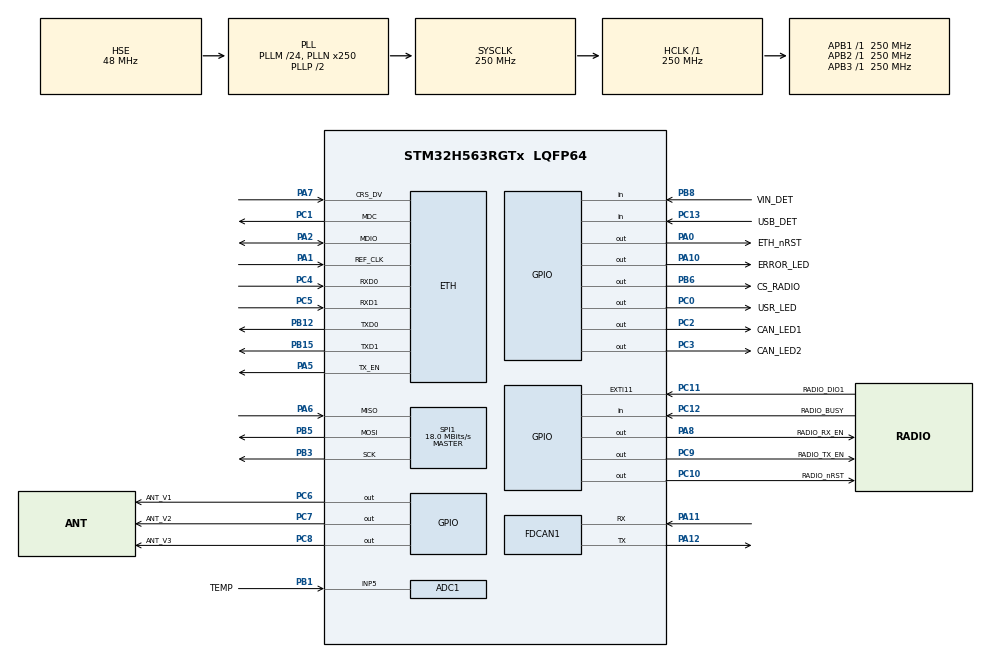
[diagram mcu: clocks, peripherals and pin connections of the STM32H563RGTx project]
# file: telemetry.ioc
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ADC1.Channel-1\#ChannelRegularConversion=ADC_CHANNEL_5
ADC1.MonitoredBy-1\#ChannelRegularConversion=__NULL
ADC1.NbrOfConversionFlag=1
ADC1.OffsetNumber-1\#ChannelRegularConversion=ADC_OFFSET_NONE
ADC1.Rank-1\#ChannelRegularConversion=1
ADC1.SamplingTime-1\#ChannelRegularConversion=ADC_SAMPLETIME_247CYCLES_5
ADC1.master=1
BOOTPATH.BootPathName=LEGACY
BOOTPATH.UserSelectedBootPath=LEGACY
CORTEX_M33_NS.AccessPermission-Cortex_Memory_Protection_Unit_Region1_Settings=MPU_REGION_ALL_RW
CORTEX_M33_NS.Attributes1=__NULL
CORTEX_M33_NS.BaseAddress-Cortex_Memory_Protection_Unit_Region1_Settings=0x20000000
CORTEX_M33_NS.DisableExec-Cortex_Memory_Protection_Unit_Region1_Settings=MPU_INSTRUCTION_ACCESS_DISABLE
CORTEX_M33_NS.Enable-Cortex_Memory_Protection_Unit_Region1_Settings=MPU_REGION_ENABLE
CORTEX_M33_NS.LimitAddress-Cortex_Memory_Protection_Unit_Region1_Settings=0x20050000
CORTEX_M33_NS.Number-Cortex_Memory_Protection_Unit_Region0_OTP_RO_AREAS_Settings=MPU_REGION_NUMBER0
CORTEX_M33_NS.default_mode_Activation=1
CORTEX_M33_NS.userName=CORTEX_M33
ETH.MediaInterface=HAL_ETH_RMII_MODE
FDCAN1.CalculateBaudRateNominal=833333
FDCAN1.CalculateTimeBitNominal=1200
FDCAN1.CalculateTimeQuantumNominal=400.0
Mcu.Family=STM32H5
Mcu.Name=STM32H563RGTx
Mcu.Package=LQFP64
NETXDUO.ETH_ON=1
NETXDUO.Initialize_ICMP_protocol=true
NETXDUO.Initialize_TCP_protocol=false
NETXDUO.LAN_8742=1
NETXDUO.NX_APP_IP_INSTANCE_THREAD_SIZE=2048
NETXDUO.NX_APP_MEM_POOL_SIZE=40*1024
NETXDUO.NX_APP_PACKET_POOL_SIZE=20
NETXDUO.NX_ENABLE_INTERFACE_CAPABILITY=false
NETXDUO.NetXDuo_Generate_Init_Code=true
NETXDUO.NetXDuo_Static_IP_address=192.168.1.50
NVIC.ETH_IRQn=true\:0\:0\:false\:false\:true\:false\:true\:true\:true
NVIC.EXTI11_IRQn=true\:0\:0\:false\:false\:true\:false\:true\:true\:true
NVIC.PriorityGroup=NVIC_PRIORITYGROUP_4
NVIC.TIM1_UP_IRQn=true\:15\:0\:false\:false\:true\:false\:false\:true\:true
NVIC.TIM2_IRQn=true\:0\:0\:false\:false\:false\:false\:true\:true\:true
NVIC.TimeBase=TIM1_UP_IRQn
NVIC.TimeBaseIP=TIM1
NetXDuo.BSP.number=1
NetXDuo0.BSP.STBoard=false
NetXDuo0.BSP.api=BSP_COMPONENT_DRIVER
NetXDuo0.BSP.component=lan8742
NetXDuo0.BSP.instance=lan8742
NetXDuo0.BSP.name=LAN_Component
NetXDuo0.BSP.semaphore=SEMA_lan8742
NetXDuo0.BSP.solution=lan8742
PA0.GPIO_Label=ETH_nRST
PA0.PinState=GPIO_PIN_SET
PA0.Signal=GPIO_Output
PA1.GPIO_Speed_Default_HIGH=GPIO_SPEED_FREQ_VERY_HIGH
PA1.Mode=RMII
PA1.Signal=ETH_REF_CLK
PA10.GPIO_Label=ERROR_LED
PA10.Signal=GPIO_Output
PA11.Mode=FDCAN_Activate
PA11.Signal=FDCAN1_RX
PA12.Mode=FDCAN_Activate
PA12.Signal=FDCAN1_TX
PA13(JTMS/SWDIO).Mode=Serial_Wire
PA13(JTMS/SWDIO).Signal=DEBUG_JTMS-SWDIO
PA14(JTCK/SWCLK).Mode=Serial_Wire
PA14(JTCK/SWCLK).Signal=DEBUG_JTCK-SWCLK
PA2.GPIO_Speed_Default_HIGH=GPIO_SPEED_FREQ_VERY_HIGH
PA2.Mode=RMII
PA2.Signal=ETH_MDIO
PA5.GPIO_Speed_Default_HIGH=GPIO_SPEED_FREQ_VERY_HIGH
PA5.Mode=RMII
PA5.Signal=ETH_TX_EN
PA6.GPIO_Speed=GPIO_SPEED_FREQ_HIGH
PA6.GPIO_Speed_Default_HIGH=GPIO_SPEED_FREQ_HIGH
PA6.Mode=Full_Duplex_Master
PA6.Signal=SPI1_MISO
PA7.GPIO_Speed_Default_HIGH=GPIO_SPEED_FREQ_VERY_HIGH
PA7.Mode=RMII
PA7.Signal=ETH_CRS_DV
PA8.GPIO_Label=RADIO_RX_EN
PA8.Signal=GPIO_Output
PB1.GPIO_Label=TEMP
PB1.Signal=ADCx_INP5
PB12.GPIO_Speed_Default_HIGH=GPIO_SPEED_FREQ_VERY_HIGH
PB12.Mode=RMII
PB12.Signal=ETH_TXD0
PB15.GPIO_Speed_Default_HIGH=GPIO_SPEED_FREQ_VERY_HIGH
PB15.Mode=RMII
PB15.Signal=ETH_TXD1
PB3(JTDO/TRACESWO).GPIO_Speed=GPIO_SPEED_FREQ_HIGH
PB3(JTDO/TRACESWO).GPIO_Speed_Default_HIGH=GPIO_SPEED_FREQ_HIGH
PB3(JTDO/TRACESWO).Mode=Full_Duplex_Master
PB3(JTDO/TRACESWO).Signal=SPI1_SCK
PB5.GPIO_Speed=GPIO_SPEED_FREQ_HIGH
PB5.GPIO_Speed_Default_HIGH=GPIO_SPEED_FREQ_HIGH
PB5.Mode=Full_Duplex_Master
PB5.Signal=SPI1_MOSI
PB6.GPIO_Label=CS_RADIO
PB6.GPIO_Speed_Default_HIGH=GPIO_SPEED_FREQ_HIGH
PB6.PinState=GPIO_PIN_SET
PB6.Signal=GPIO_Output
PB8.GPIO_Label=VIN_DET
PB8.Signal=GPIO_Input
PC0.GPIO_Label=USR_LED
PC0.Signal=GPIO_Output
PC1.GPIO_Speed_Default_HIGH=GPIO_SPEED_FREQ_VERY_HIGH
PC1.Mode=RMII
PC1.Signal=ETH_MDC
PC10.GPIO_Label=RADIO_nRST
PC10.Signal=GPIO_Output
PC11.GPIO_Label=RADIO_DIO1
PC11.Signal=GPXTI11
PC12.GPIO_Label=RADIO_BUSY
PC12.Signal=GPIO_Input
PC13.GPIO_Label=USB_DET
PC13.Signal=GPIO_Input
PC14-OSC32_IN(OSC32_IN).Mode=LSE-External-Oscillator
PC14-OSC32_IN(OSC32_IN).Signal=RCC_OSC32_IN
PC15-OSC32_OUT(OSC32_OUT).Mode=LSE-External-Oscillator
PC15-OSC32_OUT(OSC32_OUT).Signal=RCC_OSC32_OUT
PC2.GPIO_Label=CAN_LED1
PC2.Signal=GPIO_Output
PC3.GPIO_Label=CAN_LED2
PC3.Signal=GPIO_Output
PC4.GPIO_Speed_Default_HIGH=GPIO_SPEED_FREQ_VERY_HIGH
PC4.Mode=RMII
PC4.Signal=ETH_RXD0
PC5.GPIO_Speed_Default_HIGH=GPIO_SPEED_FREQ_VERY_HIGH
PC5.Mode=RMII
PC5.Signal=ETH_RXD1
PC6.GPIO_Label=ANT_V1
PC6.Signal=GPIO_Output
PC7.GPIO_Label=ANT_V2
PC7.Signal=GPIO_Output
PC8.GPIO_Label=ANT_V3
PC8.Signal=GPIO_Output
PC9.GPIO_Label=RADIO_TX_EN
PC9.Signal=GPIO_Output
PH0-OSC_IN(PH0).Mode=HSE-External-Oscillator
PH0-OSC_IN(PH0).Signal=RCC_OSC_IN
PH1-OSC_OUT(PH1).Mode=HSE-External-Oscillator
PH1-OSC_OUT(PH1).Signal=RCC_OSC_OUT
ProjectManager.HeapSize=0x200
ProjectManager.StackSize=0x400
ProjectManager.TargetToolchain=CMake
RCC.ADCCLockSelection=RCC_ADCDACCLKSOURCE_PLL2R
RCC.ADCFreq_Value=50000000
RCC.AHBFreq_Value=250000000
RCC.APB1Freq_Value=250000000
RCC.APB1TimFreq_Value=250000000
RCC.APB2Freq_Value=250000000
RCC.APB2TimFreq_Value=250000000
RCC.APB3Freq_Value=250000000
RCC.CSI_VALUE=4000000
RCC.CortexFreq_Value=250000000
RCC.EPOD_VALUE=48000000
RCC.FDCANClockSelection=RCC_FDCANCLKSOURCE_PLL2Q
RCC.HCLKFreq_Value=250000000
RCC.HSE_VALUE=48000000
RCC.HSI48_VALUE=48000000
RCC.HSI_VALUE=64000000
RCC.LSIRC_VALUE=32000
RCC.PLL1Q=10
RCC.PLL2M=48
RCC.PLL2N=200
RCC.PLL2P=10
RCC.PLL2Q=5
RCC.PLL2R=4
RCC.PLL2Source=RCC_PLL2_SOURCE_HSE
RCC.PLL3M=12
RCC.PLL3N=90
RCC.PLL3P=20
RCC.PLL3Source=RCC_PLL3_SOURCE_HSE
RCC.PLLFRACN=0
RCC.PLLM=24
RCC.PLLN=250
RCC.PLLSourceVirtual=RCC_PLL1_SOURCE_HSE
RCC.SPI1CLockSelection=RCC_SPI1CLKSOURCE_PLL3P
RCC.SYSCLKFreq_VALUE=250000000
RCC.SYSCLKSource=RCC_SYSCLKSOURCE_PLLCLK
RCC.USBFreq_Value=48000000
RCC.VCOOutputFreq_Value=500000000
SH.ADCx_INP5.0=ADC1_INP5,IN5-Single-Ended
SPI1.BaudRatePrescaler=SPI_BAUDRATEPRESCALER_BYPASS
SPI1.CalculateBaudRate=18.0 MBits/s
SPI1.DataSize=SPI_DATASIZE_8BIT
SPI1.Direction=SPI_DIRECTION_2LINES
SPI1.MasterKeepIOState=SPI_MASTER_KEEP_IO_STATE_ENABLE
SPI1.Mode=SPI_MODE_MASTER
SPI1.VirtualType=VM_MASTER
THREADX.TX_APP_GENERATE_INIT_CODE=true
TIM2.Channel-Output\ Compare1\ No\ Output=TIM_CHANNEL_1
TIM2.Prescaler=249
VP_BOOTPATH_VS_BOOTPATH.Mode=BP_Activate
VP_CORTEX_M33_NS_VS_Hclk.Mode=Hclk_Mode
VP_ICACHE_VS_ICACHE.Mode=DirectMappedCache
VP_MEMORYMAP_VS_MEMORYMAP.Mode=CurAppReg
VP_NETXDUO_VS_EthernetOoPhyOoInterface.Mode=LAN8742_Phy_Interface
VP_NETXDUO_VS_NXOoCore.Mode=NX_Core
VP_NETXDUO_VS_NetworkOoInterface.Mode=Ethernet_Interface
VP_PWR_VS_LPOM.Mode=PowerOptimisation
VP_PWR_VS_SECSignals.Mode=Security/Privilege
VP_PWR_V_PVD_IN.Mode=Mode_PVD_Int
VP_SYS_VS_tim1.Mode=TIM1
VP_THREADX_VS_RTOSJjThreadXJjCoreJjDefault.Mode=Core_Default
VP_TIM2_VS_ClockSourceINT.Mode=Internal
VP_TIM2_VS_no_output1.Mode=Output Compare1 No Output
board=custom

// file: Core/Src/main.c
/* USER CODE BEGIN Header */
/**
  ******************************************************************************
  * @file           : main.c
  * @brief          : Main program body
  ******************************************************************************
  * @attention
  *
  * Copyright (c) 2026 STMicroelectronics.
  * All rights reserved.
  *
  * This software is licensed under terms that can be found in the LICENSE file
  * in the root directory of this software component.
  * If no LICENSE file comes with this software, it is provided AS-IS.
  *
  ******************************************************************************
  */
/* USER CODE END Header */
#include "app_threadx.h"
#include "main.h"
#include "adc.h"
#include "eth.h"
#include "fdcan.h"
#include "icache.h"
#include "spi.h"
#include "tim.h"
#include "gpio.h"

/* USER CODE BEGIN Includes */
#include "app_main.h"

/* USER CODE END Includes */

void SystemClock_Config(void);
void PeriphCommonClock_Config(void);
static void MPU_Config(void);

int main(void)
{

  /* MCU Configuration--------------------------------------------------------*/

  /* MPU Configuration--------------------------------------------------------*/
  MPU_Config();

  /* Reset of all peripherals, Initializes the Flash interface and the Systick. */
  HAL_Init();

  /* Configure the system clock */
  SystemClock_Config();

  /* Configure the peripherals common clocks */
  PeriphCommonClock_Config();

  /* Initialize all configured peripherals */
  MX_GPIO_Init();
  MX_ADC1_Init();
  MX_ETH_Init();
  MX_FDCAN1_Init();
  MX_ICACHE_Init();
  MX_SPI1_Init();
  MX_TIM2_Init();
  /* USER CODE BEGIN 2 */
  app_early_init();

  /* USER CODE END 2 */

  MX_ThreadX_Init();

  /* We should never get here as control is now taken by the scheduler */

  /* Infinite loop */
  while (1)
  {

  }
}

void SystemClock_Config(void)
{
  RCC_OscInitTypeDef RCC_OscInitStruct = {0};
  RCC_ClkInitTypeDef RCC_ClkInitStruct = {0};

  /** Configure the main internal regulator output voltage
  */
  __HAL_PWR_VOLTAGESCALING_CONFIG(PWR_REGULATOR_VOLTAGE_SCALE0);

  while(!__HAL_PWR_GET_FLAG(PWR_FLAG_VOSRDY)) {}

  /** Initializes the RCC Oscillators according to the specified parameters
  * in the RCC_OscInitTypeDef structure.
  */
  RCC_OscInitStruct.OscillatorType = RCC_OSCILLATORTYPE_HSE;
  RCC_OscInitStruct.HSEState = RCC_HSE_ON;
  RCC_OscInitStruct.PLL.PLLState = RCC_PLL_ON;
  RCC_OscInitStruct.PLL.PLLSource = RCC_PLL1_SOURCE_HSE;
  RCC_OscInitStruct.PLL.PLLM = 24;
  RCC_OscInitStruct.PLL.PLLN = 250;
  RCC_OscInitStruct.PLL.PLLP = 2;
  RCC_OscInitStruct.PLL.PLLQ = 10;
  RCC_OscInitStruct.PLL.PLLR = 2;
  RCC_OscInitStruct.PLL.PLLRGE = RCC_PLL1_VCIRANGE_1;
  RCC_OscInitStruct.PLL.PLLVCOSEL = RCC_PLL1_VCORANGE_WIDE;
  RCC_OscInitStruct.PLL.PLLFRACN = 0;
  if (HAL_RCC_OscConfig(&RCC_OscInitStruct) != HAL_OK)
  {
    Error_Handler();
  }

  /** Initializes the CPU, AHB and APB buses clocks
  */
  RCC_ClkInitStruct.ClockType = RCC_CLOCKTYPE_HCLK|RCC_CLOCKTYPE_SYSCLK
                              |RCC_CLOCKTYPE_PCLK1|RCC_CLOCKTYPE_PCLK2
                              |RCC_CLOCKTYPE_PCLK3;
  RCC_ClkInitStruct.SYSCLKSource = RCC_SYSCLKSOURCE_PLLCLK;
  RCC_ClkInitStruct.AHBCLKDivider = RCC_SYSCLK_DIV1;
  RCC_ClkInitStruct.APB1CLKDivider = RCC_HCLK_DIV1;
  RCC_ClkInitStruct.APB2CLKDivider = RCC_HCLK_DIV1;
  RCC_ClkInitStruct.APB3CLKDivider = RCC_HCLK_DIV1;

  if (HAL_RCC_ClockConfig(&RCC_ClkInitStruct, FLASH_LATENCY_5) != HAL_OK)
  {
    Error_Handler();
  }

  /** Configure the programming delay
  */
  __HAL_FLASH_SET_PROGRAM_DELAY(FLASH_PROGRAMMING_DELAY_2);
}

void PeriphCommonClock_Config(void)
{
  RCC_PeriphCLKInitTypeDef PeriphClkInitStruct = {0};

  /** Initializes the peripherals clock
  */
  PeriphClkInitStruct.PeriphClockSelection = RCC_PERIPHCLK_ADCDAC|RCC_PERIPHCLK_FDCAN;
  PeriphClkInitStruct.PLL2.PLL2Source = RCC_PLL2_SOURCE_HSE;
  PeriphClkInitStruct.PLL2.PLL2M = 48;
  PeriphClkInitStruct.PLL2.PLL2N = 200;
  PeriphClkInitStruct.PLL2.PLL2P = 10;
  PeriphClkInitStruct.PLL2.PLL2Q = 5;
  PeriphClkInitStruct.PLL2.PLL2R = 4;
  PeriphClkInitStruct.PLL2.PLL2RGE = RCC_PLL2_VCIRANGE_0;
  PeriphClkInitStruct.PLL2.PLL2VCOSEL = RCC_PLL2_VCORANGE_MEDIUM;
  PeriphClkInitStruct.PLL2.PLL2FRACN = 0;
  PeriphClkInitStruct.PLL2.PLL2ClockOut = RCC_PLL2_DIVQ|RCC_PLL2_DIVR;
  PeriphClkInitStruct.FdcanClockSelection = RCC_FDCANCLKSOURCE_PLL2Q;
  PeriphClkInitStruct.AdcDacClockSelection = RCC_ADCDACCLKSOURCE_PLL2R;
  if (HAL_RCCEx_PeriphCLKConfig(&PeriphClkInitStruct) != HAL_OK)
  {
    Error_Handler();
  }
}

 /* MPU Configuration */

void MPU_Config(void)
{
  MPU_Region_InitTypeDef MPU_InitStruct = {0};
  MPU_Attributes_InitTypeDef MPU_AttributesInit = {0};

  /* Disables the MPU */
  HAL_MPU_Disable();

  /** Initializes and configures the Region 0 and the memory to be protected
  */
  MPU_InitStruct.Enable = MPU_REGION_ENABLE;
  MPU_InitStruct.Number = MPU_REGION_NUMBER0;
  MPU_InitStruct.BaseAddress = 0x08FFF000;
  MPU_InitStruct.LimitAddress = 0x08FFFFFF;
  MPU_InitStruct.AttributesIndex = MPU_ATTRIBUTES_NUMBER0;
  MPU_InitStruct.AccessPermission = MPU_REGION_ALL_RO;
  MPU_InitStruct.DisableExec = MPU_INSTRUCTION_ACCESS_DISABLE;
  MPU_InitStruct.IsShareable = MPU_ACCESS_NOT_SHAREABLE;

  HAL_MPU_ConfigRegion(&MPU_InitStruct);

  /** Initializes and configures the Region 1 and the memory to be protected
  */
  MPU_InitStruct.Number = MPU_REGION_NUMBER1;
  MPU_InitStruct.BaseAddress = 0x20000000;
  MPU_InitStruct.LimitAddress = 0x20050000;
  MPU_InitStruct.AccessPermission = MPU_REGION_ALL_RW;

  HAL_MPU_ConfigRegion(&MPU_InitStruct);

  /** Initializes and configures the Attribute 0 and the memory to be protected
  */
  MPU_AttributesInit.Number = MPU_ATTRIBUTES_NUMBER0;
  MPU_AttributesInit.Attributes = INNER_OUTER(MPU_NOT_CACHEABLE);

  HAL_MPU_ConfigMemoryAttributes(&MPU_AttributesInit);
  /* Enables the MPU */
  HAL_MPU_Enable(MPU_PRIVILEGED_DEFAULT);

}

void HAL_TIM_PeriodElapsedCallback(TIM_HandleTypeDef *htim)
{
  if (htim->Instance == TIM1)
  {
    HAL_IncTick();
  }
}

void Error_Handler(void)
{
  __disable_irq();
  while (1)
  {
  }
}
